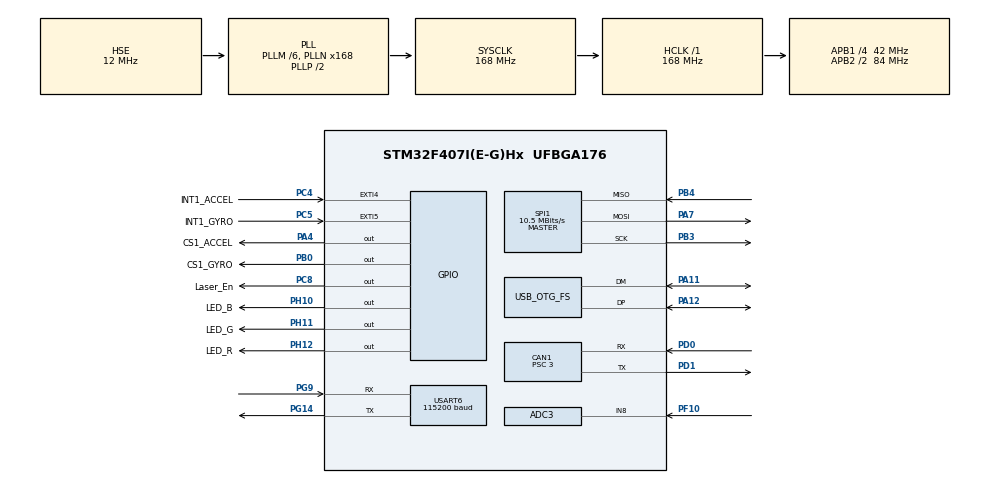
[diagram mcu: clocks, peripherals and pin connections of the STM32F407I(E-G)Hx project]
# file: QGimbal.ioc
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ADC3.Channel-0\#ChannelRegularConversion=ADC_CHANNEL_8
ADC3.InjNumberOfConversion=0
ADC3.NbrOfConversionFlag=1
ADC3.Rank-0\#ChannelRegularConversion=1
ADC3.SamplingTime-0\#ChannelRegularConversion=ADC_SAMPLETIME_15CYCLES
CAN1.BS1=CAN_BS1_7TQ
CAN1.BS2=CAN_BS2_6TQ
CAN1.CalculateBaudRate=1000000
CAN1.CalculateTimeBit=1000
CAN1.CalculateTimeQuantum=71.42857142857143
CAN1.NART=ENABLE
CAN1.Prescaler=3
CAN1.SJW=CAN_SJW_2TQ
Dma.Request0=SPI1_TX
Dma.Request1=SPI1_RX
Dma.Request2=USART6_TX
Dma.Request3=USART6_RX
Dma.SPI1_RX.1.Direction=DMA_PERIPH_TO_MEMORY
Dma.SPI1_RX.1.FIFOMode=DMA_FIFOMODE_DISABLE
Dma.SPI1_RX.1.Instance=DMA2_Stream0
Dma.SPI1_RX.1.MemDataAlignment=DMA_MDATAALIGN_BYTE
Dma.SPI1_RX.1.MemInc=DMA_MINC_ENABLE
Dma.SPI1_RX.1.Mode=DMA_NORMAL
Dma.SPI1_RX.1.PeriphDataAlignment=DMA_PDATAALIGN_BYTE
Dma.SPI1_RX.1.PeriphInc=DMA_PINC_DISABLE
Dma.SPI1_RX.1.Priority=DMA_PRIORITY_HIGH
Dma.SPI1_TX.0.Direction=DMA_MEMORY_TO_PERIPH
Dma.SPI1_TX.0.FIFOMode=DMA_FIFOMODE_DISABLE
Dma.SPI1_TX.0.Instance=DMA2_Stream3
Dma.SPI1_TX.0.MemDataAlignment=DMA_MDATAALIGN_BYTE
Dma.SPI1_TX.0.MemInc=DMA_MINC_ENABLE
Dma.SPI1_TX.0.Mode=DMA_NORMAL
Dma.SPI1_TX.0.PeriphDataAlignment=DMA_PDATAALIGN_BYTE
Dma.SPI1_TX.0.PeriphInc=DMA_PINC_DISABLE
Dma.SPI1_TX.0.Priority=DMA_PRIORITY_HIGH
Dma.USART6_RX.3.Direction=DMA_PERIPH_TO_MEMORY
Dma.USART6_RX.3.FIFOMode=DMA_FIFOMODE_DISABLE
Dma.USART6_RX.3.Instance=DMA2_Stream1
Dma.USART6_RX.3.MemDataAlignment=DMA_MDATAALIGN_BYTE
Dma.USART6_RX.3.MemInc=DMA_MINC_ENABLE
Dma.USART6_RX.3.Mode=DMA_NORMAL
Dma.USART6_RX.3.PeriphDataAlignment=DMA_PDATAALIGN_BYTE
Dma.USART6_RX.3.PeriphInc=DMA_PINC_DISABLE
Dma.USART6_RX.3.Priority=DMA_PRIORITY_MEDIUM
Dma.USART6_TX.2.Direction=DMA_MEMORY_TO_PERIPH
Dma.USART6_TX.2.FIFOMode=DMA_FIFOMODE_DISABLE
Dma.USART6_TX.2.Instance=DMA2_Stream6
Dma.USART6_TX.2.MemDataAlignment=DMA_MDATAALIGN_BYTE
Dma.USART6_TX.2.MemInc=DMA_MINC_ENABLE
Dma.USART6_TX.2.Mode=DMA_NORMAL
Dma.USART6_TX.2.PeriphDataAlignment=DMA_PDATAALIGN_BYTE
Dma.USART6_TX.2.PeriphInc=DMA_PINC_DISABLE
Dma.USART6_TX.2.Priority=DMA_PRIORITY_LOW
FREERTOS.Tasks01=DebugTask,24,128,StartDebugTask,As weak,NULL,Dynamic,NULL,NULL;ImuTask,48,128,StartImuTask,As external,NULL,Dynamic,NULL,NULL;GimbalTask,40,256,StartGimbalTask,As external,NULL,Dynamic,NULL,NULL;CommunicateTask,24,256,StartCommunicateTask,As external,NULL,Dynamic,NULL,NULL;StartShell,24,128,StartStartShell,As external,NULL,Dynamic,NULL,NULL
Mcu.Family=STM32F4
Mcu.Name=STM32F407I(E-G)Hx
Mcu.Package=UFBGA176
NVIC.CAN1_RX0_IRQn=true\:5\:0\:true\:false\:true\:true\:true\:true\:true
NVIC.CAN1_RX1_IRQn=true\:5\:0\:true\:false\:true\:true\:true\:true\:true
NVIC.DMA2_Stream0_IRQn=true\:5\:0\:true\:false\:true\:true\:false\:true\:true
NVIC.DMA2_Stream1_IRQn=true\:5\:0\:true\:false\:true\:true\:false\:true\:true
NVIC.DMA2_Stream3_IRQn=true\:5\:0\:true\:false\:true\:true\:false\:true\:true
NVIC.DMA2_Stream6_IRQn=true\:5\:0\:true\:false\:true\:true\:false\:true\:true
NVIC.EXTI4_IRQn=true\:5\:0\:true\:false\:true\:true\:true\:true\:true
NVIC.EXTI9_5_IRQn=true\:5\:0\:true\:false\:true\:true\:true\:true\:true
NVIC.OTG_FS_IRQn=true\:5\:0\:false\:false\:true\:true\:false\:true\:true
NVIC.PriorityGroup=NVIC_PRIORITYGROUP_4
NVIC.SPI1_IRQn=true\:5\:0\:false\:false\:true\:true\:true\:true\:true
NVIC.USART6_IRQn=true\:5\:0\:false\:false\:true\:true\:true\:true\:true
PA11.Mode=Device_Only
PA11.Signal=USB_OTG_FS_DM
PA12.Mode=Device_Only
PA12.Signal=USB_OTG_FS_DP
PA13.Mode=Serial_Wire
PA13.Signal=SYS_JTMS-SWDIO
PA14.Mode=Serial_Wire
PA14.Signal=SYS_JTCK-SWCLK
PA4.GPIO_Label=CS1_ACCEL
PA4.Signal=GPIO_Output
PA7.GPIO_Speed=GPIO_SPEED_FREQ_LOW
PA7.Mode=Full_Duplex_Master
PA7.Signal=SPI1_MOSI
PB0.GPIO_Label=CS1_GYRO
PB0.Signal=GPIO_Output
PB3.GPIO_Speed=GPIO_SPEED_FREQ_LOW
PB3.Mode=Full_Duplex_Master
PB3.Signal=SPI1_SCK
PB4.GPIO_Speed=GPIO_SPEED_FREQ_LOW
PB4.Mode=Full_Duplex_Master
PB4.Signal=SPI1_MISO
PC14-OSC32_IN.Mode=LSE-External-Oscillator
PC14-OSC32_IN.Signal=RCC_OSC32_IN
PC15-OSC32_OUT.Mode=LSE-External-Oscillator
PC15-OSC32_OUT.Signal=RCC_OSC32_OUT
PC4.GPIO_Label=INT1_ACCEL
PC4.GPIO_ModeDefaultEXTI=GPIO_MODE_IT_FALLING
PC4.Signal=GPXTI4
PC5.GPIO_Label=INT1_GYRO
PC5.GPIO_ModeDefaultEXTI=GPIO_MODE_IT_FALLING
PC5.Signal=GPXTI5
PC8.GPIO_Label=Laser_En
PC8.Signal=GPIO_Output
PD0.Mode=CAN_Activate
PD0.Signal=CAN1_RX
PD1.Mode=CAN_Activate
PD1.Signal=CAN1_TX
PF10.Mode=IN8
PF10.Signal=ADC3_IN8
PG14.Mode=Asynchronous
PG14.Signal=USART6_TX
PG9.Mode=Asynchronous
PG9.Signal=USART6_RX
PH0-OSC_IN.Mode=HSE-External-Oscillator
PH0-OSC_IN.Signal=RCC_OSC_IN
PH1-OSC_OUT.Mode=HSE-External-Oscillator
PH1-OSC_OUT.Signal=RCC_OSC_OUT
PH10.GPIO_Label=LED_B
PH10.Signal=GPIO_Output
PH11.GPIO_Label=LED_G
PH11.Signal=GPIO_Output
PH12.GPIO_Label=LED_R
PH12.PinState=GPIO_PIN_SET
PH12.Signal=GPIO_Output
ProjectManager.HeapSize=0x800
ProjectManager.StackSize=0x1000
ProjectManager.TargetToolchain=CMake
RCC.48MHZClocksFreq_Value=48000000
RCC.AHBFreq_Value=168000000
RCC.APB1CLKDivider=RCC_HCLK_DIV4
RCC.APB1Freq_Value=42000000
RCC.APB1TimFreq_Value=84000000
RCC.APB2CLKDivider=RCC_HCLK_DIV2
RCC.APB2Freq_Value=84000000
RCC.APB2TimFreq_Value=168000000
RCC.CortexFreq_Value=168000000
RCC.HCLKFreq_Value=168000000
RCC.HSE_VALUE=12000000
RCC.HSI_VALUE=16000000
RCC.PLLM=6
RCC.PLLN=168
RCC.PLLQ=7
RCC.SYSCLKFreq_VALUE=168000000
RCC.SYSCLKSource=RCC_SYSCLKSOURCE_PLLCLK
RCC.VCOOutputFreq_Value=336000000
SPI1.BaudRatePrescaler=SPI_BAUDRATEPRESCALER_8
SPI1.CLKPhase=SPI_PHASE_2EDGE
SPI1.CLKPolarity=SPI_POLARITY_HIGH
SPI1.CalculateBaudRate=10.5 MBits/s
SPI1.Direction=SPI_DIRECTION_2LINES
SPI1.Mode=SPI_MODE_MASTER
SPI1.VirtualType=VM_MASTER
USART6.BaudRate=115200
USART6.VirtualMode=VM_ASYNC
USB_DEVICE.CLASS_NAME_FS=CDC
USB_DEVICE.PID_CDC_FS=22433
USB_DEVICE.PRODUCT_STRING_CDC_FS=QGimbal ComPort
USB_DEVICE.VirtualMode-CDC_FS=Cdc
USB_DEVICE.VirtualModeFS=Cdc_FS
USB_OTG_FS.VirtualMode=Device_Only
VP_FREERTOS_VS_CMSIS_V2.Mode=CMSIS_V2
VP_USB_DEVICE_VS_USB_DEVICE_CDC_FS.Mode=CDC_FS
board=custom

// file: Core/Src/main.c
/* USER CODE BEGIN Header */
/**
  ******************************************************************************
  * @file           : main.c
  * @brief          : Main program body
  ******************************************************************************
  * @attention
  *
  * Copyright (c) 2025 STMicroelectronics.
  * All rights reserved.
  *
  * This software is licensed under terms that can be found in the LICENSE file
  * in the root directory of this software component.
  * If no LICENSE file comes with this software, it is provided AS-IS.
  *
  ******************************************************************************
  */
/* USER CODE END Header */
#include "main.h"
#include "cmsis_os.h"
#include "adc.h"
#include "can.h"
#include "dma.h"
#include "spi.h"
#include "usart.h"
#include "usb_device.h"
#include "gpio.h"

void SystemClock_Config(void);
void MX_FREERTOS_Init(void);

int main(void)
{

  /* MCU Configuration--------------------------------------------------------*/

  /* Reset of all peripherals, Initializes the Flash interface and the Systick. */
  HAL_Init();

  /* Configure the system clock */
  SystemClock_Config();

  /* Initialize all configured peripherals */
  MX_GPIO_Init();
  MX_DMA_Init();
  MX_SPI1_Init();
  MX_CAN1_Init();
  MX_USART6_UART_Init();
  MX_ADC3_Init();

  /* Init scheduler */
  osKernelInitialize();

  /* Call init function for freertos objects (in cmsis_os2.c) */
  MX_FREERTOS_Init();

  /* Start scheduler */
  osKernelStart();

  /* We should never get here as control is now taken by the scheduler */

  /* Infinite loop */
  while (1)
  {

  }
}

void SystemClock_Config(void)
{
  RCC_OscInitTypeDef RCC_OscInitStruct = {0};
  RCC_ClkInitTypeDef RCC_ClkInitStruct = {0};

  /** Configure the main internal regulator output voltage
  */
  __HAL_RCC_PWR_CLK_ENABLE();
  __HAL_PWR_VOLTAGESCALING_CONFIG(PWR_REGULATOR_VOLTAGE_SCALE1);

  /** Initializes the RCC Oscillators according to the specified parameters
  * in the RCC_OscInitTypeDef structure.
  */
  RCC_OscInitStruct.OscillatorType = RCC_OSCILLATORTYPE_HSE;
  RCC_OscInitStruct.HSEState = RCC_HSE_ON;
  RCC_OscInitStruct.PLL.PLLState = RCC_PLL_ON;
  RCC_OscInitStruct.PLL.PLLSource = RCC_PLLSOURCE_HSE;
  RCC_OscInitStruct.PLL.PLLM = 6;
  RCC_OscInitStruct.PLL.PLLN = 168;
  RCC_OscInitStruct.PLL.PLLP = RCC_PLLP_DIV2;
  RCC_OscInitStruct.PLL.PLLQ = 7;
  if (HAL_RCC_OscConfig(&RCC_OscInitStruct) != HAL_OK)
  {
    Error_Handler();
  }

  /** Initializes the CPU, AHB and APB buses clocks
  */
  RCC_ClkInitStruct.ClockType = RCC_CLOCKTYPE_HCLK|RCC_CLOCKTYPE_SYSCLK
                              |RCC_CLOCKTYPE_PCLK1|RCC_CLOCKTYPE_PCLK2;
  RCC_ClkInitStruct.SYSCLKSource = RCC_SYSCLKSOURCE_PLLCLK;
  RCC_ClkInitStruct.AHBCLKDivider = RCC_SYSCLK_DIV1;
  RCC_ClkInitStruct.APB1CLKDivider = RCC_HCLK_DIV4;
  RCC_ClkInitStruct.APB2CLKDivider = RCC_HCLK_DIV2;

  if (HAL_RCC_ClockConfig(&RCC_ClkInitStruct, FLASH_LATENCY_5) != HAL_OK)
  {
    Error_Handler();
  }
}

/* USER CODE BEGIN 4 */
extern void Reset_Handler(void); /* 声明定义在 startup_stm32f407xx.s 中的复位函数 */
extern uint32_t _estack;         /* 声明定义在 ld 脚本里的栈顶地址 */

__attribute__((section(".flash_bootloader"), used))
const uint32_t boot_vector[2] = {
  (uint32_t)&_estack,         /* 硬件自动读取作为 SP */
  (uint32_t)&Reset_Handler    /* 硬件自动读取作为 PC，直接跳到系统正常的启动汇编 */
};
/* USER CODE END 4 */

void Error_Handler(void)
{
  __disable_irq();
  while (1)
  {
  }
}

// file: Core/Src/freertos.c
/* USER CODE BEGIN Header */
/**
  ******************************************************************************
  * File Name          : freertos.c
  * Description        : Code for freertos applications
  ******************************************************************************
  * @attention
  *
  * Copyright (c) 2025 STMicroelectronics.
  * All rights reserved.
  *
  * This software is licensed under terms that can be found in the LICENSE file
  * in the root directory of this software component.
  * If no LICENSE file comes with this software, it is provided AS-IS.
  *
  ******************************************************************************
  */
/* USER CODE END Header */

#include "FreeRTOS.h"
#include "task.h"
#include "main.h"
#include "cmsis_os.h"

/* USER CODE BEGIN Includes */
#include "task_public.h"
/* USER CODE END Includes */

/* Definitions for DebugTask */
osThreadId_t DebugTaskHandle;
const osThreadAttr_t DebugTask_attributes = {
  .name = "DebugTask",
  .stack_size = 128 * 4,
  .priority = (osPriority_t) osPriorityNormal,
};
/* Definitions for ImuTask */
osThreadId_t ImuTaskHandle;
const osThreadAttr_t ImuTask_attributes = {
  .name = "ImuTask",
  .stack_size = 128 * 4,
  .priority = (osPriority_t) osPriorityRealtime,
};
/* Definitions for GimbalTask */
osThreadId_t GimbalTaskHandle;
const osThreadAttr_t GimbalTask_attributes = {
  .name = "GimbalTask",
  .stack_size = 256 * 4,
  .priority = (osPriority_t) osPriorityHigh,
};
/* Definitions for CommunicateTask */
osThreadId_t CommunicateTaskHandle;
const osThreadAttr_t CommunicateTask_attributes = {
  .name = "CommunicateTask",
  .stack_size = 256 * 4,
  .priority = (osPriority_t) osPriorityNormal,
};
/* Definitions for StartShell */
osThreadId_t StartShellHandle;
const osThreadAttr_t StartShell_attributes = {
  .name = "StartShell",
  .stack_size = 128 * 4,
  .priority = (osPriority_t) osPriorityNormal,
};

void StartDebugTask(void *argument);
extern void StartImuTask(void *argument);
extern void StartGimbalTask(void *argument);
extern void StartCommunicateTask(void *argument);
extern void StartStartShell(void *argument);

extern void MX_USB_DEVICE_Init(void);
void MX_FREERTOS_Init(void); /* (MISRA C 2004 rule 8.1) */

void MX_FREERTOS_Init(void) {

  /* Create the thread(s) */
  /* creation of DebugTask */
  DebugTaskHandle = osThreadNew(StartDebugTask, NULL, &DebugTask_attributes);

  /* creation of ImuTask */
  ImuTaskHandle = osThreadNew(StartImuTask, NULL, &ImuTask_attributes);

  /* creation of GimbalTask */
  GimbalTaskHandle = osThreadNew(StartGimbalTask, NULL, &GimbalTask_attributes);

  /* creation of CommunicateTask */
  CommunicateTaskHandle = osThreadNew(StartCommunicateTask, NULL, &CommunicateTask_attributes);

  /* creation of StartShell */
  StartShellHandle = osThreadNew(StartStartShell, NULL, &StartShell_attributes);

}

__weak void StartDebugTask(void *argument)
{
  /* init code for USB_DEVICE */
  MX_USB_DEVICE_Init();
  for(;;)
  {
    osDelay(1);
  }
}
